# ATmega64HVE2 device description
Architecture: AVR8; Family: megaAVR
Programming and debug interfaces: ISP, HVSP, debugWIRE
Registers are 8-bit, access not given, no defined reset value unless marked. A register's access mark holds for its fields unless they carry their own. Offsets are from the block's base; lines under a group give offsets from that group; [hi:lo] are bit positions; {n}, {i} and the like mark numbered series; 'fields as' and 'values as' point back to an identical list; <NAME> marks a mode.

## Ordering variants
standard: 3.0 to 3.6 V

## Memory
prog space: start 0x0000 size 0x10000, little endian
  0x0000 FLASH size 0x10000 flash, rw, executable, page 0x80
  0xfc00 BOOT_SECTION_1 size 0x0400 flash, rw, executable, page 0x80
  0xf800 BOOT_SECTION_2 size 0x0800 flash, rw, executable, page 0x80
  0xf000 BOOT_SECTION_3 size 0x1000 flash, rw, executable, page 0x80
  0xe000 BOOT_SECTION_4 size 0x2000 flash, rw, executable, page 0x80
signatures space: start 0 size 3, little endian
  0 SIGNATURES size 3 signatures, ro
fuses space: start 0 size 0x0002, little endian
  0 FUSES size 0x0002 fuses, rw
lockbits space: start 0 size 0x0001, little endian
  0 LOCKBITS size 0x0001 lockbits, rw
data space: start 0x0000 size 0x1100, little endian
  0x0000 REGISTERS size 0x0020 regs
  0x0020 MAPPED_IO size 0x00e0 io
  0x0100 IRAM size 0x1000 ram
eeprom space: start 0x0000 size 0x0400, little endian
  0x0000 EEPROM size 0x0400 eeprom, rw, page 0x04
io space: start 0x00 size 0x40, little endian

## Peripheral instances (address, pins/pin function, parameters)
SPI at 0x00 — Serial Peripheral Interface
EEPROM at 0x00
TC1 at 0x00 — Timer/Counter, 16-bit
TC0 at 0x00 — Timer/Counter, 16-bit
PORTB at 0x00 — I/O Port
PORTA at 0x00 — I/O Port
BOOT_LOAD at 0x00 — Bootloader
ADC at 0x00 — Analog-to-Digital Converter
BANDGAP at 0x00
LINUART at 0x00 — Local Interconnect Network
CPU at 0x00 — CPU Registers
  parameters: CORE_VERSION=V2E
EXINT at 0x00 — External Interrupts
WDT at 0x00 — Watchdog Timer
WAKEUP_TIMER at 0x00
FUSE at 0 in fuses — Fuses
LOCKBIT at 0 in lockbits — Lockbits

## Interrupts
0 RESET — External Pin, Power-on Reset, Brown-out Reset and Watchdog Reset
1 INT0 — External Interrupt 0
2 PCINT0 — Pin Change Interrupt 0
3 PCINT1 — Pin Change Interrupt 1
4 WDT — Watchdog Timeout Interrupt
5 WAKEUP — Wakeup Timer Overflow
6 TIMER1_IC — Timer 1 Input capture
7 TIMER1_COMPA — Timer 1 Compare Match A
8 TIMER1_COMPB — Timer 1 Compare Match B
9 TIMER1_OVF — Timer 1 overflow
10 TIMER0_IC — Timer 0 Input Capture
11 TIMER0_COMPA — Timer 0 Comapre Match A
12 TIMER0_COMPB — Timer 0 Compare Match B
13 TIMER0_OVF — Timer 0 Overflow
14 LIN_STATUS — LIN Status Interrupt
15 LIN_ERROR — LIN Error Interrupt
16 SPI_STC — SPI Serial transfer complete
17 VADC_CONV — Voltage ADC Instantaneous Conversion Complete
18 VADC_ACC — Voltage ADC Accumulated Conversion Complete
19 CADC_CONV — C-ADC Instantaneous Conversion Complete
20 CADC_REG_CUR — C-ADC Regular Current
21 CADC_ACC — C-ADC Accumulated Conversion Complete
22 EE_READY — EEPROM Ready
23 SPM — SPM Ready
24 PLL — PLL Lock Change Interrupt

## Properties
SIGNATURES: JTAGID=0x9610, SIGNATURE0=0x1e, SIGNATURE1=0x96, SIGNATURE2=0x10
OCD: OCD_REVISION=1, OCD_DATAREG=0x31, PROGBASE=0x0000

## FUSE — Fuses
Instances: FUSE 0 in fuses
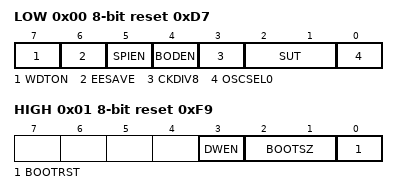
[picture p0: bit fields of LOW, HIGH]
0x00 LOW reset 0xD7
  [7] WDTON — Watch-dog Timer always on
  [6] EESAVE — Preserve EEPROM through the Chip Erase cycle
  [5] SPIEN — Serial program downloading (SPI) enabled
  [4] BODEN — Brown-out detection enabled
  [3] CKDIV8 — Divide clock by 8
  [2:1] SUT — Select start-up time
    0=14CK_0MS (Start-up time 14 CK + 0 ms); 1=14CK_16MS (Start-up time 14 CK + 16 ms); 2=14CK_32MS (Start-up time 14 CK + 32 ms); 3=14CK_64MS (Start-up time 14 CK + 64 ms)
  [0] OSCSEL0 — Oscillator select
0x01 HIGH reset 0xF9
  [3] DWEN — Debug Wire enable
  [2:1] BOOTSZ — Select Boot Size
    3=512W_7E00 (Boot Flash size=512 words Boot address=$7E00); 2=1024W_7C00 (Boot Flash size=1024 words Boot address=$7C00); 1=2048W_7800 (Boot Flash size=2048 words Boot address=$7800); 0=4096W_7000 (Boot Flash size=4096 words Boot address=$7000)
  [0] BOOTRST — Boot Reset vector Enabled
